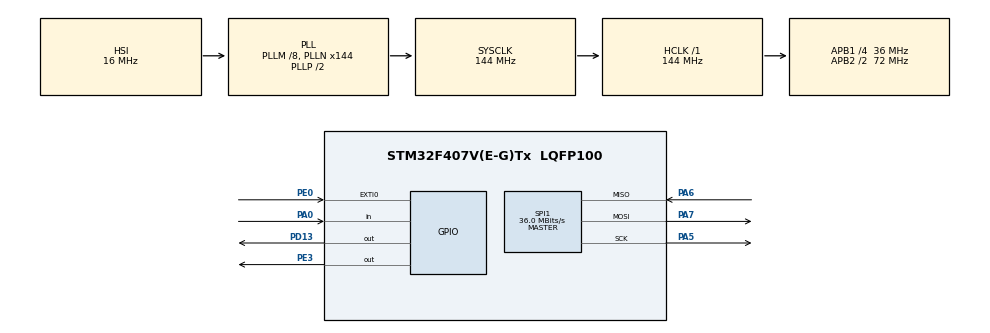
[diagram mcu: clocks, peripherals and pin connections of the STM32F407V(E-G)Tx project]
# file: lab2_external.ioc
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Mcu.Family=STM32F4
Mcu.Name=STM32F407V(E-G)Tx
Mcu.Package=LQFP100
NVIC.EXTI0_IRQn=true\:0\:0\:false\:false\:true\:true\:true\:true
NVIC.PriorityGroup=NVIC_PRIORITYGROUP_4
PA0-WKUP.Signal=GPIO_Input
PA13.Mode=Serial_Wire
PA13.Signal=SYS_JTMS-SWDIO
PA14.Mode=Serial_Wire
PA14.Signal=SYS_JTCK-SWCLK
PA5.Mode=Full_Duplex_Master
PA5.Signal=SPI1_SCK
PA6.Mode=Full_Duplex_Master
PA6.Signal=SPI1_MISO
PA7.Mode=Full_Duplex_Master
PA7.Signal=SPI1_MOSI
PD13.Signal=GPIO_Output
PE0.Signal=GPXTI0
PE3.Signal=GPIO_Output
ProjectManager.HeapSize=0x200
ProjectManager.StackSize=0x400
ProjectManager.TargetToolchain=STM32CubeIDE
RCC.48MHZClocksFreq_Value=72000000
RCC.AHBFreq_Value=144000000
RCC.APB1CLKDivider=RCC_HCLK_DIV4
RCC.APB1Freq_Value=36000000
RCC.APB1TimFreq_Value=72000000
RCC.APB2CLKDivider=RCC_HCLK_DIV2
RCC.APB2Freq_Value=72000000
RCC.APB2TimFreq_Value=144000000
RCC.CortexFreq_Value=144000000
RCC.HCLKFreq_Value=144000000
RCC.HSE_VALUE=25000000
RCC.HSI_VALUE=16000000
RCC.LSE_VALUE=32768
RCC.PLLM=8
RCC.PLLN=144
RCC.SYSCLKFreq_VALUE=144000000
RCC.SYSCLKSource=RCC_SYSCLKSOURCE_PLLCLK
RCC.VCOOutputFreq_Value=288000000
SPI1.CalculateBaudRate=36.0 MBits/s
SPI1.Direction=SPI_DIRECTION_2LINES
SPI1.Mode=SPI_MODE_MASTER
SPI1.VirtualType=VM_MASTER
board=custom

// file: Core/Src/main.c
/* USER CODE BEGIN Header */
/**
  ******************************************************************************
  * @file           : main.c
  * @brief          : Main program body
  ******************************************************************************
  */
/* USER CODE END Header */
#include "main.h"
#include "spi.h"
#include "gpio.h"

/* USER CODE BEGIN Includes */
#include "MY_LIS3DSH.h"
/* USER CODE END Includes */

void SystemClock_Config(void);

/* USER CODE BEGIN 0 */
LIS3DSH_Data_t myAccelData; // Структура для зберігання координат X, Y, Z
/* USER CODE END 0 */

int main(void)
{

  /* MCU Configuration--------------------------------------------------------*/

  /* Reset of all peripherals, Initializes the Flash interface and the Systick. */
  HAL_Init();

  /* Configure the system clock */
  SystemClock_Config();

  /* Initialize all configured peripherals */
  MX_GPIO_Init();
  MX_SPI1_Init();

  /* USER CODE BEGIN 2 */
  LIS3DSH_Init(&hspi1); // Ініціалізація акселерометра LIS3DSH по SPI1
  /* USER CODE END 2 */

  /* Infinite loop */
  while (1)
  {

    /* USER CODE BEGIN 3 */
    // Зчитуємо поточні значення прискорення/нахилу
    LIS3DSH_GetData(&myAccelData);

    // Варіант 2: Керування помаранчевим світлодіодом (PD13)
    if (myAccelData.Y > 1000 || myAccelData.Y < -1000)
    {
        HAL_GPIO_WritePin(GPIOD, GPIO_PIN_13, GPIO_PIN_SET);   // Увімкнути Orange (PD13)
    }
    else
    {
        HAL_GPIO_WritePin(GPIOD, GPIO_PIN_13, GPIO_PIN_RESET); // Вимкнути Orange (PD13)
    }

    HAL_Delay(50); // Невелика затримка для стабілізації зчитування
  }
  /* USER CODE END 3 */
}

void SystemClock_Config(void)
{
  RCC_OscInitTypeDef RCC_OscInitStruct = {0};
  RCC_ClkInitTypeDef RCC_ClkInitStruct = {0};

  /** Configure the main internal regulator output voltage
  */
  __HAL_RCC_PWR_CLK_ENABLE();
  __HAL_PWR_VOLTAGESCALING_CONFIG(PWR_REGULATOR_VOLTAGE_SCALE1);

  /** Initializes the RCC Oscillators according to the specified parameters
  * in the RCC_OscInitTypeDef structure.
  */
  RCC_OscInitStruct.OscillatorType = RCC_OSCILLATORTYPE_HSI;
  RCC_OscInitStruct.HSIState = RCC_HSI_ON;
  RCC_OscInitStruct.HSICalibrationValue = RCC_HSICALIBRATION_DEFAULT;
  RCC_OscInitStruct.PLL.PLLState = RCC_PLL_ON;
  RCC_OscInitStruct.PLL.PLLSource = RCC_PLLSOURCE_HSI;
  RCC_OscInitStruct.PLL.PLLM = 8;
  RCC_OscInitStruct.PLL.PLLN = 144;
  RCC_OscInitStruct.PLL.PLLP = RCC_PLLP_DIV2;
  RCC_OscInitStruct.PLL.PLLQ = 4;
  if (HAL_RCC_OscConfig(&RCC_OscInitStruct) != HAL_OK)
  {
    Error_Handler();
  }

  /** Initializes the CPU, AHB and APB buses clocks
  */
  RCC_ClkInitStruct.ClockType = RCC_CLOCKTYPE_HCLK|RCC_CLOCKTYPE_SYSCLK
                              |RCC_CLOCKTYPE_PCLK1|RCC_CLOCKTYPE_PCLK2;
  RCC_ClkInitStruct.SYSCLKSource = RCC_SYSCLKSOURCE_PLLCLK;
  RCC_ClkInitStruct.AHBCLKDivider = RCC_SYSCLK_DIV1;
  RCC_ClkInitStruct.APB1CLKDivider = RCC_HCLK_DIV4;
  RCC_ClkInitStruct.APB2CLKDivider = RCC_HCLK_DIV2;

  if (HAL_RCC_ClockConfig(&RCC_ClkInitStruct, FLASH_LATENCY_4) != HAL_OK)
  {
    Error_Handler();
  }
}

void Error_Handler(void)
{
  __disable_irq();
  while (1)
  {
  }
}
